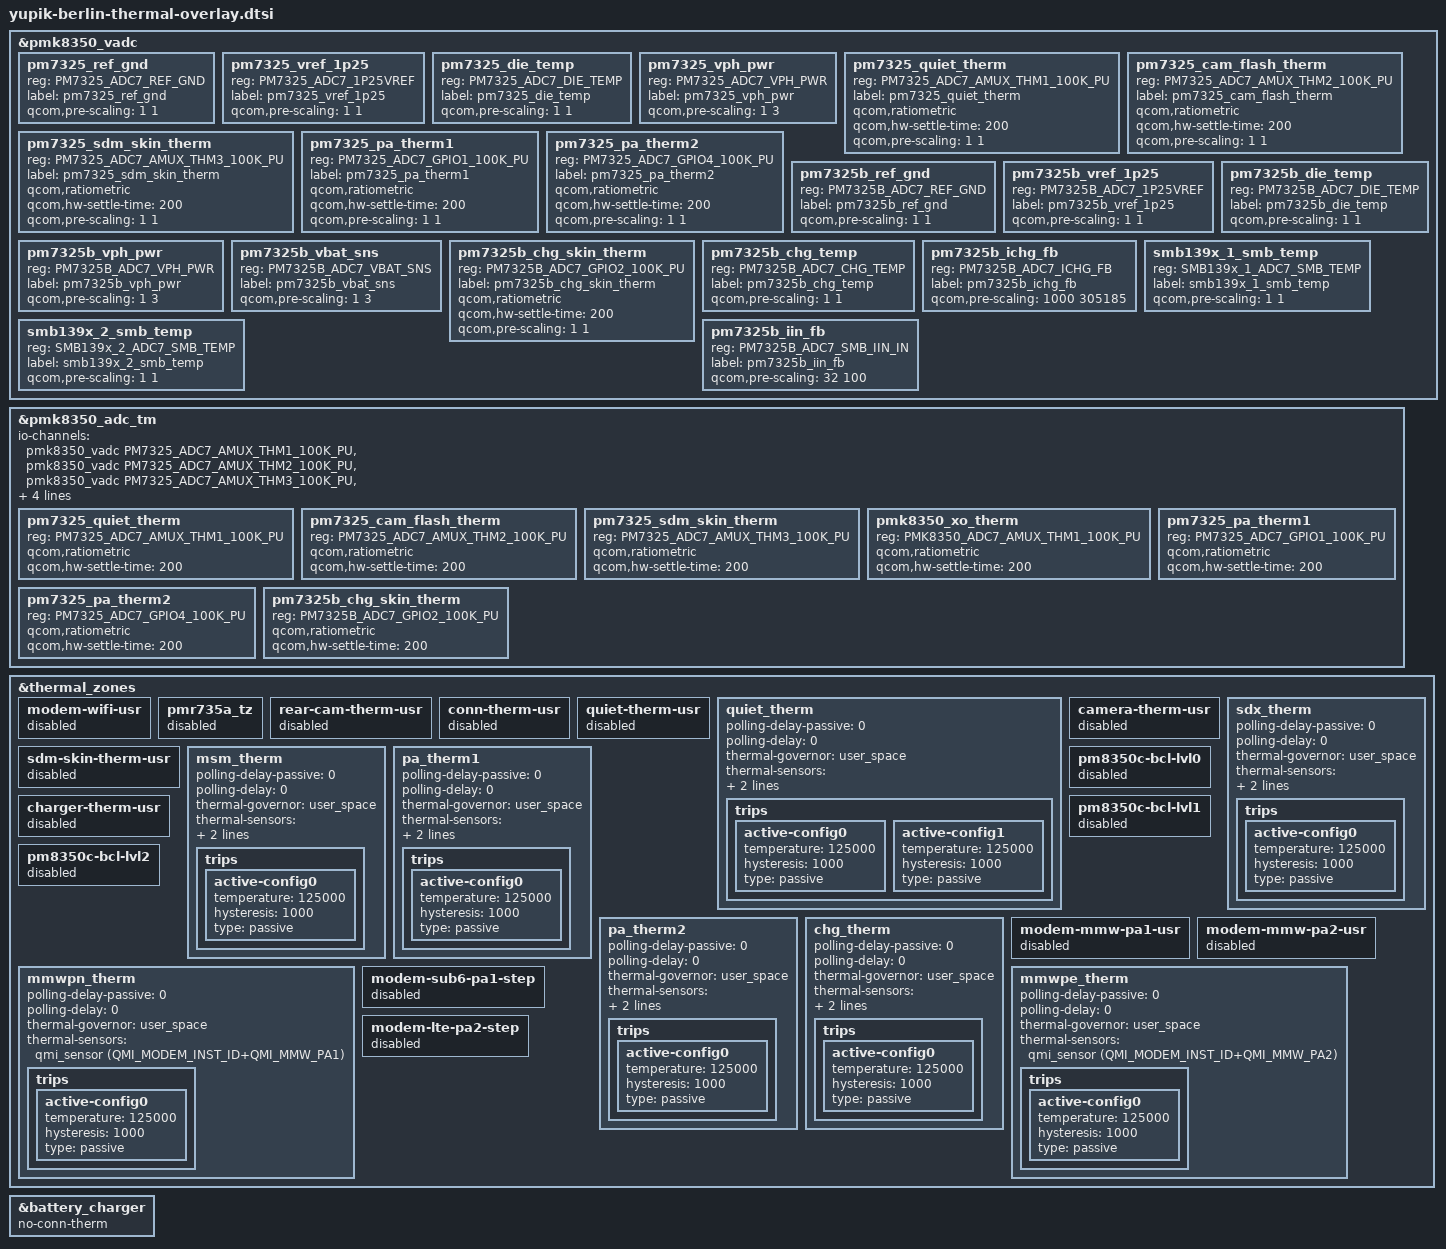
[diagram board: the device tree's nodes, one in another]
#include "moto_therm_sys_temp.dtsi"

&pmk8350_vadc {
	/delete-node/ pm8350_ref_gnd;
	/delete-node/ pm8350_vref_1p25;
	/delete-node/ pm8350_die_temp;
	/delete-node/ pm8350_vph_pwr;

	/delete-node/ pm8350b_ref_gnd;
	/delete-node/ pm8350b_vref_1p25;
	/delete-node/ pm8350b_die_temp;
	/delete-node/ pm8350b_vph_pwr;
	/delete-node/ pm8350b_vbat_sns;

	/delete-node/ pmr735b_ref_gnd;
	/delete-node/ pmr735b_vref_1p25;
	/delete-node/ pmr735b_die_temp;

	/* PM7325 Channel nodes */
	pm7325_ref_gnd {
		reg = <PM7325_ADC7_REF_GND>;
		label = "pm7325_ref_gnd";
		qcom,pre-scaling = <1 1>;
	};

	pm7325_vref_1p25 {
		reg = <PM7325_ADC7_1P25VREF>;
		label = "pm7325_vref_1p25";
		qcom,pre-scaling = <1 1>;
	};

	pm7325_die_temp {
		reg = <PM7325_ADC7_DIE_TEMP>;
		label = "pm7325_die_temp";
		qcom,pre-scaling = <1 1>;
	};

	pm7325_vph_pwr {
		reg = <PM7325_ADC7_VPH_PWR>;
		label = "pm7325_vph_pwr";
		qcom,pre-scaling = <1 3>;
	};

	pm7325_quiet_therm {
		reg = <PM7325_ADC7_AMUX_THM1_100K_PU>;
		label = "pm7325_quiet_therm";
		qcom,ratiometric;
		qcom,hw-settle-time = <200>;
		qcom,pre-scaling = <1 1>;
	};

	pm7325_cam_flash_therm {
		reg = <PM7325_ADC7_AMUX_THM2_100K_PU>;
		label = "pm7325_cam_flash_therm";
		qcom,ratiometric;
		qcom,hw-settle-time = <200>;
		qcom,pre-scaling = <1 1>;
	};

	pm7325_sdm_skin_therm {
		reg = <PM7325_ADC7_AMUX_THM3_100K_PU>;
		label = "pm7325_sdm_skin_therm";
		qcom,ratiometric;
		qcom,hw-settle-time = <200>;
		qcom,pre-scaling = <1 1>;
	};

	/delete-node/ pm7325_wide_rfc_therm;

	pm7325_pa_therm1 {
		reg = <PM7325_ADC7_GPIO1_100K_PU>;
		label = "pm7325_pa_therm1";
		qcom,ratiometric;
		qcom,hw-settle-time = <200>;
		qcom,pre-scaling = <1 1>;
	};

	pm7325_pa_therm2 {
		reg = <PM7325_ADC7_GPIO4_100K_PU>;
		label = "pm7325_pa_therm2";
		qcom,ratiometric;
		qcom,hw-settle-time = <200>;
		qcom,pre-scaling = <1 1>;
	};

	pm7325b_ref_gnd {
		reg = <PM7325B_ADC7_REF_GND>;
		label = "pm7325b_ref_gnd";
		qcom,pre-scaling = <1 1>;
	};

	pm7325b_vref_1p25 {
		reg = <PM7325B_ADC7_1P25VREF>;
		label = "pm7325b_vref_1p25";
		qcom,pre-scaling = <1 1>;
	};

	pm7325b_die_temp {
		reg = <PM7325B_ADC7_DIE_TEMP>;
		label = "pm7325b_die_temp";
		qcom,pre-scaling = <1 1>;
	};

	pm7325b_vph_pwr {
		reg = <PM7325B_ADC7_VPH_PWR>;
		label = "pm7325b_vph_pwr";
		qcom,pre-scaling = <1 3>;
	};

	pm7325b_vbat_sns {
		reg = <PM7325B_ADC7_VBAT_SNS>;
		label = "pm7325b_vbat_sns";
		qcom,pre-scaling = <1 3>;
	};

	/delete-node/ pm7325b_usb_conn_therm;

	pm7325b_chg_skin_therm {
		reg = <PM7325B_ADC7_GPIO2_100K_PU>;
		label = "pm7325b_chg_skin_therm";
		qcom,ratiometric;
		qcom,hw-settle-time = <200>;
		qcom,pre-scaling = <1 1>;
	};

	pm7325b_chg_temp {
		reg = <PM7325B_ADC7_CHG_TEMP>;
		label = "pm7325b_chg_temp";
		qcom,pre-scaling = <1 1>;
	};

	pm7325b_ichg_fb {
		reg = <PM7325B_ADC7_ICHG_FB>;
		label = "pm7325b_ichg_fb";
		qcom,pre-scaling = <1000 305185>;
	};

	smb139x_1_smb_temp {
		reg = <SMB139x_1_ADC7_SMB_TEMP>;
		label = "smb139x_1_smb_temp";
		qcom,pre-scaling = <1 1>;
	};

	smb139x_2_smb_temp {
		reg = <SMB139x_2_ADC7_SMB_TEMP>;
		label = "smb139x_2_smb_temp";
		qcom,pre-scaling = <1 1>;
	};

	pm7325b_iin_fb {
		reg = <PM7325B_ADC7_SMB_IIN_IN>;
		label = "pm7325b_iin_fb";
		qcom,pre-scaling = <32 100>;
	};
};

&pmk8350_adc_tm {
	/delete-property/ io-channels;
	io-channels = <&pmk8350_vadc PM7325_ADC7_AMUX_THM1_100K_PU>,
			<&pmk8350_vadc PM7325_ADC7_AMUX_THM2_100K_PU>,
			<&pmk8350_vadc PM7325_ADC7_AMUX_THM3_100K_PU>,
			<&pmk8350_vadc PM7325_ADC7_GPIO1_100K_PU>,
			<&pmk8350_vadc PM7325_ADC7_GPIO4_100K_PU>,
			<&pmk8350_vadc PMK8350_ADC7_AMUX_THM1_100K_PU>,
			<&pmk8350_vadc PM7325B_ADC7_GPIO2_100K_PU>;

	pm7325_quiet_therm {
		reg = <PM7325_ADC7_AMUX_THM1_100K_PU>;
		qcom,ratiometric;
		qcom,hw-settle-time = <200>;
	};

	pm7325_cam_flash_therm {
		reg = <PM7325_ADC7_AMUX_THM2_100K_PU>;
		qcom,ratiometric;
		qcom,hw-settle-time = <200>;
	};

	pm7325_sdm_skin_therm {
		reg = <PM7325_ADC7_AMUX_THM3_100K_PU>;
		qcom,ratiometric;
		qcom,hw-settle-time = <200>;
	};

	pmk8350_xo_therm {
		reg = <PMK8350_ADC7_AMUX_THM1_100K_PU>;
		qcom,ratiometric;
		qcom,hw-settle-time = <200>;
	};

	/delete-node/ pm7325_wide_rfc_therm ;

	pm7325_pa_therm1 {
		reg = <PM7325_ADC7_GPIO1_100K_PU>;
		qcom,ratiometric;
		qcom,hw-settle-time = <200>;
	};

	pm7325_pa_therm2 {
		reg = <PM7325_ADC7_GPIO4_100K_PU>;
		qcom,ratiometric;
		qcom,hw-settle-time = <200>;
	};

	/delete-node/ pm7325b_usb_conn_therm;

	pm7325b_chg_skin_therm {
		reg = <PM7325B_ADC7_GPIO2_100K_PU>;
		qcom,ratiometric;
		qcom,hw-settle-time = <200>;
	};
};

&thermal_zones {
	modem-wifi-usr {
		status = "disabled";
	};
	pmr735a_tz {
		status = "disabled";
	};
	rear-cam-therm-usr {
		status = "disabled";
	};
	conn-therm-usr {
		status = "disabled";
	};

	quiet-therm-usr {
		status = "disabled";
	};
	quiet_therm {
		polling-delay-passive = <0>;
		polling-delay = <0>;
		thermal-governor = "user_space";
		thermal-sensors = <&pmk8350_adc_tm PM7325_ADC7_AMUX_THM1_100K_PU>;
		wake-capable-sensor;
		trips {
			active-config0 {
				temperature = <125000>;
				hysteresis = <1000>;
				type = "passive";
			};

			active-config1 {
				temperature = <125000>;
				hysteresis = <1000>;
				type = "passive";
			};
		};
	};

	camera-therm-usr {
		status = "disabled";
	};
	sdx_therm {
		polling-delay-passive = <0>;
		polling-delay = <0>;
		thermal-governor = "user_space";
		thermal-sensors = <&pmk8350_adc_tm PM7325_ADC7_AMUX_THM2_100K_PU>;
		wake-capable-sensor;
		trips {
			active-config0 {
				temperature = <125000>;
				hysteresis = <1000>;
				type = "passive";
			};
		};
	};

	sdm-skin-therm-usr {
		status = "disabled";
	};
	msm_therm {
		polling-delay-passive = <0>;
		polling-delay = <0>;
		thermal-governor = "user_space";
		thermal-sensors = <&pmk8350_adc_tm PM7325_ADC7_AMUX_THM3_100K_PU>;
		wake-capable-sensor;
		trips {
			active-config0 {
				temperature = <125000>;
				hysteresis = <1000>;
				type = "passive";
			};
		};
	};

	pa_therm1 {
		polling-delay-passive = <0>;
		polling-delay = <0>;
		thermal-governor = "user_space";
		thermal-sensors = <&pmk8350_adc_tm PM7325_ADC7_GPIO1_100K_PU>;
		wake-capable-sensor;
		trips {
			active-config0 {
				temperature = <125000>;
				hysteresis = <1000>;
				type = "passive";
			};
		};
	};
	pa_therm2 {
		polling-delay-passive = <0>;
		polling-delay = <0>;
		thermal-governor = "user_space";
		thermal-sensors = <&pmk8350_adc_tm PM7325_ADC7_GPIO4_100K_PU>;
		wake-capable-sensor;
		trips {
			active-config0 {
				temperature = <125000>;
				hysteresis = <1000>;
				type = "passive";
			};
		};
	};

	charger-therm-usr {
		status = "disabled";
	};
	chg_therm {
		polling-delay-passive = <0>;
		polling-delay = <0>;
		thermal-governor = "user_space";
		thermal-sensors = <&pmk8350_adc_tm PM7325B_ADC7_GPIO2_100K_PU>;
		wake-capable-sensor;
		trips {
			active-config0 {
				temperature = <125000>;
				hysteresis = <1000>;
				type = "passive";
			};
		};
	};

	pm8350c-bcl-lvl0 {
		status = "disabled";
	};
	pm8350c-bcl-lvl1 {
		status = "disabled";
	};
	pm8350c-bcl-lvl2 {
		status = "disabled";
	};

	modem-mmw-pa1-usr {
		status = "disabled";
	};
	mmwpn_therm {
		polling-delay-passive = <0>;
		polling-delay = <0>;
		thermal-governor = "user_space";
		thermal-sensors = <&qmi_sensor
				(QMI_MODEM_INST_ID+QMI_MMW_PA1)>;
		trips {
			active-config0 {
				temperature = <125000>;
				hysteresis = <1000>;
				type = "passive";
			};
		};
	};

	modem-mmw-pa2-usr {
		status = "disabled";
	};
	mmwpe_therm {
		polling-delay-passive = <0>;
		polling-delay = <0>;
		thermal-governor = "user_space";
		thermal-sensors = <&qmi_sensor
				(QMI_MODEM_INST_ID+QMI_MMW_PA2)>;
		trips {
			active-config0 {
				temperature = <125000>;
				hysteresis = <1000>;
				type = "passive";
			};
		};
	};
	modem-sub6-pa1-step {
		status = "disabled";
	};
	modem-lte-pa2-step {
		status = "disabled";
	};
};

&battery_charger {
	no-conn-therm;
};
